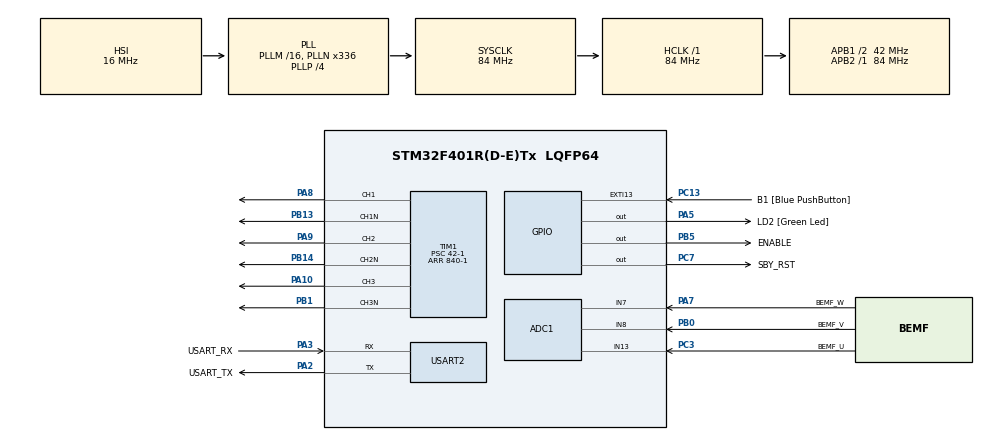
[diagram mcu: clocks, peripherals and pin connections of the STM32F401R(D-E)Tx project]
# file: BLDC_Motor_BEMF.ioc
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Mcu.Family=STM32F4
PA2.GPIO_PuPd=GPIO_NOPULL
RCC.CortexFreq_Value=84000000
TIM1.OCIdleState_1=TIM_OCIDLESTATE_RESET
TIM1.OCIdleState_2=TIM_OCIDLESTATE_RESET
TIM1.OCIdleState_3=TIM_OCIDLESTATE_RESET
PA14.GPIO_Label=TCK
PA3.GPIO_PuPd=GPIO_NOPULL
PA2.GPIO_Speed=GPIO_SPEED_FREQ_LOW
PB0.GPIO_Label=BEMF_V
PA3.GPIO_Speed=GPIO_SPEED_FREQ_LOW
PB13.Signal=TIM1_CH1N
RCC.SYSCLKSource=RCC_SYSCLKSOURCE_PLLCLK
ProjectManager.StackSize=0x400
TIM1.Prescaler=42-1
PH0\ -\ OSC_IN.Signal=RCC_OSC_IN
RCC.HCLKFreq_Value=84000000
RCC.APB2TimFreq_Value=84000000
TIM3.Period=24000-1
Dma.ADC1.0.Direction=DMA_PERIPH_TO_MEMORY
ADC1.Channel-2\#ChannelRegularConversion=ADC_CHANNEL_7
PC7.Signal=GPIO_Output
PB5.PinState=GPIO_PIN_SET
TIM1.AutomaticOutput=TIM_AUTOMATICOUTPUT_ENABLE
PC3.Signal=ADCx_IN13
NVIC.DMA2_Stream0_IRQn=true\:0\:0\:false\:false\:true\:false\:true
Dma.ADC1.0.MemDataAlignment=DMA_MDATAALIGN_WORD
RCC.AHBFreq_Value=84000000
ADC1.Channel-0\#ChannelRegularConversion=ADC_CHANNEL_13
NVIC.TIM1_TRG_COM_TIM11_IRQn=true\:0\:0\:false\:false\:true\:true\:true
RCC.HSE_VALUE=8000000
ADC1.ScanConvMode=ENABLE
PC13-ANTI_TAMP.Signal=GPXTI13
ADC1.Rank-2\#ChannelRegularConversion=3
PC14-OSC32_IN.Mode=LSE-External-Oscillator
PA14.Mode=Serial_Wire
PB14.Mode=PWM Generation2 CH2 CH2N
TIM3.Prescaler=254-1
PA5.GPIO_PuPd=GPIO_NOPULL
Dma.ADC1.0.PeriphInc=DMA_PINC_DISABLE
TIM1.DeadTime=16
SH.ADCx_IN8.0=ADC1_IN8,IN8
PC7.PinState=GPIO_PIN_SET
PA8.Signal=S_TIM1_CH1
ADC1.SamplingTime-0\#ChannelRegularConversion=ADC_SAMPLETIME_28CYCLES
Mcu.Package=LQFP64
PB1.Signal=TIM1_CH3N
USART2.VirtualMode=VM_ASYNC
PA2.GPIO_Label=USART_TX
PA10.Signal=S_TIM1_CH3
PB5.GPIO_Label=ENABLE
TIM1.BreakState=TIM_BREAK_ENABLE
RCC.APB1TimFreq_Value=84000000
Dma.ADC1.0.FIFOMode=DMA_FIFOMODE_DISABLE
TIM1.Period=840-1
PB13.Mode=PWM Generation1 CH1 CH1N
Dma.Request0=ADC1
ADC1.EOCSelection=ADC_EOC_SEQ_CONV
VP_TIM3_VS_ClockSourceINT.Mode=Internal
PA3.Signal=USART2_RX
PA2.GPIO_Mode=GPIO_MODE_AF_PP
PB3.GPIO_Label=SWO
PC15-OSC32_OUT.Mode=LSE-External-Oscillator
PC7.GPIO_ModeDefaultOutputPP=GPIO_MODE_OUTPUT_OD
SH.ADCx_IN13.0=ADC1_IN13,IN13
Dma.ADC1.0.Instance=DMA2_Stream0
ADC1.Rank-0\#ChannelRegularConversion=1
TIM1.OffStateIDLEMode=TIM_OSSI_ENABLE
PC13-ANTI_TAMP.GPIO_PuPd=GPIO_NOPULL
PC13-ANTI_TAMP.GPIO_Label=B1 [Blue PushButton]
TIM1.CounterMode=TIM_COUNTERMODE_CENTERALIGNED1
PH1\ -\ OSC_OUT.Mode=HSE-External-Clock-Source
TIM1.Channel-PWM\ Generation1\ CH1\ CH1N=TIM_CHANNEL_1
RCC.APB1CLKDivider=RCC_HCLK_DIV2
PC14-OSC32_IN.Signal=RCC_OSC32_IN
ADC1.SamplingTime-2\#ChannelRegularConversion=ADC_SAMPLETIME_28CYCLES
PA3.Mode=Asynchronous
PA13.Signal=SYS_JTMS-SWDIO
TIM1.Channel-PWM\ Generation2\ CH2\ CH2N=TIM_CHANNEL_2
Dma.ADC1.0.PeriphDataAlignment=DMA_PDATAALIGN_WORD
PH0\ -\ OSC_IN.Mode=HSE-External-Clock-Source
SH.S_TIM1_CH1.0=TIM1_CH1,PWM Generation1 CH1 CH1N
ProjectManager.TargetToolchain=STM32CubeIDE
SH.ADCx_IN7.0=ADC1_IN7,IN7
Dma.ADC1.0.Mode=DMA_CIRCULAR
PA3.GPIO_Mode=GPIO_MODE_AF_PP
Dma.ADC1.0.Priority=DMA_PRIORITY_VERY_HIGH
PA9.Signal=S_TIM1_CH2
ADC1.Channel-1\#ChannelRegularConversion=ADC_CHANNEL_8
TIM1.Channel-PWM\ Generation3\ CH3\ CH3N=TIM_CHANNEL_3
PC15-OSC32_OUT.Signal=RCC_OSC32_OUT
PB14.Signal=TIM1_CH2N
PA5.Signal=GPIO_Output
PH1\ -\ OSC_OUT.Signal=RCC_OSC_OUT
board=NUCLEO-F401RE
RCC.VCOOutputFreq_Value=336000000
TIM1.OCNIdleState_3=TIM_OCNIDLESTATE_RESET
TIM1.OCNIdleState_2=TIM_OCNIDLESTATE_RESET
TIM1.OCNIdleState_1=TIM_OCNIDLESTATE_RESET
RCC.APB2Freq_Value=84000000
SH.S_TIM1_CH2.0=TIM1_CH2,PWM Generation2 CH2 CH2N
TIM1.OffStateRunMode=TIM_OSSR_ENABLE
ADC1.DMAContinuousRequests=ENABLE
ADC1.NbrOfConversion=3
PA13.Mode=Serial_Wire
Mcu.Name=STM32F401R(D-E)Tx
PA2.Signal=USART2_TX
PA13.GPIO_Label=TMS
ADC1.ExternalTrigConv=ADC_SOFTWARE_START
PC7.GPIO_Label=SBY_RST
RCC.48MHZClocksFreq_Value=48000000
PB3.Signal=SYS_JTDO-SWO
ADC1.SamplingTime-1\#ChannelRegularConversion=ADC_SAMPLETIME_28CYCLES
RCC.SYSCLKFreq_VALUE=84000000
PB5.Signal=GPIO_Output
PA7.GPIO_Label=BEMF_W
ADC1.master=1
PA5.GPIO_Label=LD2 [Green Led]
TIM3.TIM_MasterSlaveMode=TIM_MASTERSLAVEMODE_ENABLE
PC13-ANTI_TAMP.GPIO_ModeDefaultEXTI=GPIO_MODE_IT_FALLING
ADC1.Rank-1\#ChannelRegularConversion=2
PA14.Signal=SYS_JTCK-SWCLK
Dma.ADC1.0.MemInc=DMA_MINC_ENABLE
ProjectManager.HeapSize=0x200
PB1.Mode=PWM Generation3 CH3 CH3N
SH.S_TIM1_CH3.0=TIM1_CH3,PWM Generation3 CH3 CH3N
NVIC.TIM1_UP_TIM10_IRQn=true\:0\:0\:false\:false\:true\:true\:true
RCC.HSI_VALUE=16000000
RCC.PLLP=RCC_PLLP_DIV4
PA5.GPIO_Speed=GPIO_SPEED_FREQ_LOW
RCC.PLLQ=7
NVIC.PriorityGroup=NVIC_PRIORITYGROUP_0
ADC1.NbrOfConversionFlag=1
RCC.PLLN=336
PA2.Mode=Asynchronous
PC3.GPIO_Label=BEMF_U
TIM3.TIM_MasterOutputTrigger=TIM_TRGO_UPDATE
RCC.APB1Freq_Value=42000000
PA5.GPIO_Mode=GPIO_MODE_OUTPUT_PP
PB0.Signal=ADCx_IN8
TIM1.TIM_MasterSlaveMode=TIM_MASTERSLAVEMODE_DISABLE
PA3.GPIO_Label=USART_RX
PA7.Signal=ADCx_IN7

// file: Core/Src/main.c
/* USER CODE BEGIN Header */
/**
  ******************************************************************************
  * @file           : main.c
  * @brief          : Main program body
  ******************************************************************************
  * @attention
  *
  * <h2><center>&copy; Copyright (c) 2021 STMicroelectronics.
  * All rights reserved.</center></h2>
  *
  * This software component is licensed by ST under BSD 3-Clause license,
  * the "License"; You may not use this file except in compliance with the
  * License. You may obtain a copy of the License at:
  *                        opensource.org/licenses/BSD-3-Clause
  *
  ******************************************************************************
  */
/* USER CODE END Header */
#include "main.h"
#include "adc.h"
#include "dma.h"
#include "tim.h"
#include "usart.h"
#include "gpio.h"

void SystemClock_Config(void);

int main(void)
{

  /* MCU Configuration--------------------------------------------------------*/

  /* Reset of all peripherals, Initializes the Flash interface and the Systick. */
  HAL_Init();

  /* Configure the system clock */
  SystemClock_Config();

  /* Initialize all configured peripherals */
  MX_GPIO_Init();
  MX_DMA_Init();
  MX_USART2_UART_Init();
  MX_TIM1_Init();
  MX_TIM3_Init();
  MX_ADC1_Init();
  /* USER CODE BEGIN 2 */
    uint32_t dir = CW;
    uint32_t speed = 10;

    bldc_motor_init(&htim1, &htim3);
    bldc_motor_set_speed(speed, dir);
  /* USER CODE END 2 */

  /* Infinite loop */
  /* USER CODE BEGIN WHILE */
  while (1)
  {
	  bldc_motor_process();
    /* USER CODE END WHILE */

  }
}

void SystemClock_Config(void)
{
  RCC_OscInitTypeDef RCC_OscInitStruct = {0};
  RCC_ClkInitTypeDef RCC_ClkInitStruct = {0};

  /** Configure the main internal regulator output voltage
  */
  __HAL_RCC_PWR_CLK_ENABLE();
  __HAL_PWR_VOLTAGESCALING_CONFIG(PWR_REGULATOR_VOLTAGE_SCALE2);
  /** Initializes the RCC Oscillators according to the specified parameters
  * in the RCC_OscInitTypeDef structure.
  */
  RCC_OscInitStruct.OscillatorType = RCC_OSCILLATORTYPE_HSI;
  RCC_OscInitStruct.HSIState = RCC_HSI_ON;
  RCC_OscInitStruct.HSICalibrationValue = RCC_HSICALIBRATION_DEFAULT;
  RCC_OscInitStruct.PLL.PLLState = RCC_PLL_ON;
  RCC_OscInitStruct.PLL.PLLSource = RCC_PLLSOURCE_HSI;
  RCC_OscInitStruct.PLL.PLLM = 16;
  RCC_OscInitStruct.PLL.PLLN = 336;
  RCC_OscInitStruct.PLL.PLLP = RCC_PLLP_DIV4;
  RCC_OscInitStruct.PLL.PLLQ = 7;
  if (HAL_RCC_OscConfig(&RCC_OscInitStruct) != HAL_OK)
  {
    Error_Handler();
  }
  /** Initializes the CPU, AHB and APB buses clocks
  */
  RCC_ClkInitStruct.ClockType = RCC_CLOCKTYPE_HCLK|RCC_CLOCKTYPE_SYSCLK
                              |RCC_CLOCKTYPE_PCLK1|RCC_CLOCKTYPE_PCLK2;
  RCC_ClkInitStruct.SYSCLKSource = RCC_SYSCLKSOURCE_PLLCLK;
  RCC_ClkInitStruct.AHBCLKDivider = RCC_SYSCLK_DIV1;
  RCC_ClkInitStruct.APB1CLKDivider = RCC_HCLK_DIV2;
  RCC_ClkInitStruct.APB2CLKDivider = RCC_HCLK_DIV1;

  if (HAL_RCC_ClockConfig(&RCC_ClkInitStruct, FLASH_LATENCY_2) != HAL_OK)
  {
    Error_Handler();
  }
}

/* USER CODE BEGIN 4 */
void HAL_TIMEx_CommutCallback(TIM_HandleTypeDef *htim)
{
	bldc_motor_six_step_algorithm();

}

void HAL_TIM_PeriodElapsedCallback(TIM_HandleTypeDef *htim)
{
	if(htim->Instance == TIM1)
	{
		if(SET == __HAL_TIM_IS_TIM_COUNTING_DOWN(&htim1))
		{
			bldc_motor_bemf_start_adc_conversion();
		}
	}
}

void HAL_ADC_ConvCpltCallback(ADC_HandleTypeDef* hadc)
{
	bldc_motor_bemf_calculation();
}
/* USER CODE END 4 */

void Error_Handler(void)
{
  __disable_irq();
  while (1)
  {
  }
}

/************************ (C) COPYRIGHT STMicroelectronics *****END OF FILE****/
